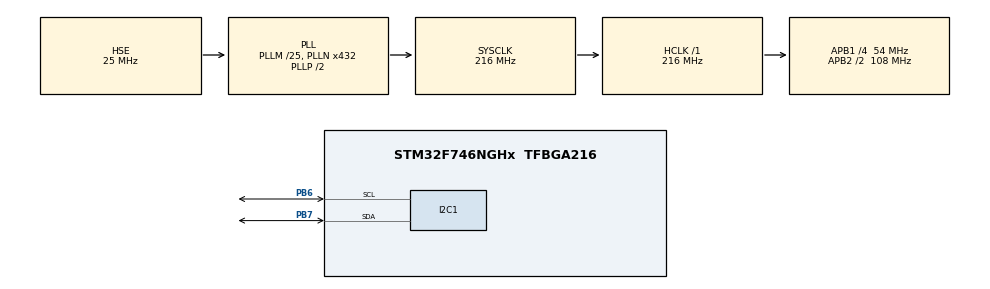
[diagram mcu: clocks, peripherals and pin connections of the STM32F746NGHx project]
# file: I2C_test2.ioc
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I2C1.Timing=0x20404768
Mcu.Family=STM32F7
Mcu.Name=STM32F746NGHx
Mcu.Package=TFBGA216
NVIC.PriorityGroup=NVIC_PRIORITYGROUP_4
PB6.GPIO_Pu=GPIO_PULLUP
PB6.Mode=I2C
PB6.Signal=I2C1_SCL
PB7.GPIO_Pu=GPIO_PULLUP
PB7.Mode=I2C
PB7.Signal=I2C1_SDA
PH0/OSC_IN.Mode=HSE-External-Oscillator
PH0/OSC_IN.Signal=RCC_OSC_IN
PH1/OSC_OUT.Mode=HSE-External-Oscillator
PH1/OSC_OUT.Signal=RCC_OSC_OUT
ProjectManager.HeapSize=0x200
ProjectManager.StackSize=0x400
ProjectManager.TargetToolchain=STM32CubeIDE
RCC.AHBFreq_Value=216000000
RCC.APB1CLKDivider=RCC_HCLK_DIV4
RCC.APB1Freq_Value=54000000
RCC.APB1TimFreq_Value=108000000
RCC.APB2CLKDivider=RCC_HCLK_DIV2
RCC.APB2Freq_Value=108000000
RCC.APB2TimFreq_Value=216000000
RCC.CortexFreq_Value=216000000
RCC.HCLKFreq_Value=216000000
RCC.HSE_VALUE=25000000
RCC.HSI_VALUE=16000000
RCC.PLL48CLockSelection=RCC_CLK48SOURCE_PLLSAIP
RCC.PLLI2SN=100
RCC.PLLM=25
RCC.PLLN=432
RCC.PLLQ=9
RCC.PLLSAIN=384
RCC.PLLSAIP=RCC_PLLSAIP_DIV8
RCC.PLLSAIR=5
RCC.PLLSAIRDiv=RCC_PLLSAIDIVR_8
RCC.PLLSourceVirtual=RCC_PLLSOURCE_HSE
RCC.SDMMCClockSelection=RCC_SDMMC1CLKSOURCE_CLK48
RCC.SYSCLKFreq_VALUE=216000000
RCC.SYSCLKSource=RCC_SYSCLKSOURCE_PLLCLK
RCC.USBFreq_Value=48000000
RCC.VCOOutputFreq_Value=432000000
board=STM32F746G-DISCO

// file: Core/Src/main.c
/* USER CODE BEGIN Header */
/**
  ******************************************************************************
  * @file           : main.c
  * @brief          : Main program body
  ******************************************************************************
  * @attention
  *
  * Copyright (c) 2025 STMicroelectronics.
  * All rights reserved.
  *
  * This software is licensed under terms that can be found in the LICENSE file
  * in the root directory of this software component.
  * If no LICENSE file comes with this software, it is provided AS-IS.
  *
  ******************************************************************************
  */
/* USER CODE END Header */
#include "main.h"
#include <string.h>
/* USER CODE BEGIN Includes */
/*7bit i2c address: 1010xxx
 * xxx depends on hardware: In our ram its EN | A9 | A8 | R/W
 * 7bits +1bit R/W
 * For factory RAM EN is 0, For application RAM EN is 1
 * After these 8 bits we need to add our address location (A7 - A0)
 * 0x50 is the device’s 7-bit address from the datasheet.
 * 0x50 << 1 (equals 0xA0) converts it to the 8-bit form STM32 HAL needs.*/
#define EEPROM_I2C_ADDR     (0xA2)    // 7-bit address shifted left for HAL
#define EEPROM_TIMEOUT      100				//This timeout defines how long the function will wait (block) for the I²C operation to complete before giving up and returning an error. It prevents your program from hanging forever if something goes wrong on the I²C bus (e.g., no device response, bus stuck, or hardware fault).
#define EEPROM_MEM_ADDR     0x00
uint8_t writeData[] = "Param";
uint8_t readData[sizeof(writeData)] = {0};
/* USER CODE END Includes */

I2C_HandleTypeDef hi2c1; //pointer to structure

void SystemClock_Config(void);
static void MX_GPIO_Init(void);
static void MX_I2C1_Init(void);

int main(void)
{

  /* USER CODE BEGIN 1 */
  HAL_Init();
  /* USER CODE END 1 */

  /* MCU Configuration--------------------------------------------------------*/

  /* Reset of all peripherals, Initializes the Flash interface and the Systick. */

  /* Configure the system clock */
  SystemClock_Config();

  /* Initialize all configured peripherals */
  MX_GPIO_Init();
  MX_I2C1_Init();
  /* USER CODE BEGIN 2 */
  /*
   * HAL_I2C_Master_Transmit(&hi2c1, EEPROM_I2C_ADDR | 0x00, data, size, timeout); // Write
  	 HAL_I2C_Master_Receive(&hi2c1,  EEPROM_I2C_ADDR | 0x01, data, size, timeout); // Read*/
  HAL_StatusTypeDef writeStatus = HAL_I2C_Mem_Write(
      &hi2c1,
      EEPROM_I2C_ADDR,
      EEPROM_MEM_ADDR,
      I2C_MEMADD_SIZE_8BIT,
      writeData,
      sizeof(writeData),
      EEPROM_TIMEOUT
  );

  HAL_Delay(5);  // EEPROM write cycle time

  /* EEPROM Read */
  HAL_StatusTypeDef readStatus = HAL_I2C_Mem_Read(
      &hi2c1,
      EEPROM_I2C_ADDR,
      EEPROM_MEM_ADDR,
      I2C_MEMADD_SIZE_8BIT,
      readData,
      sizeof(readData),
      EEPROM_TIMEOUT
  );

  /* Verify data */
  if (writeStatus == HAL_OK && readStatus == HAL_OK)
  {
      if (memcmp(writeData, readData, sizeof(writeData)) == 0)
      {
          // Data verified successfully
      }
      else
      {
          // Data mismatch
      }
  }
  /* USER CODE END 2 */

  /* Infinite loop */
  while (1)
  {

  }
}

void SystemClock_Config(void)
{
  RCC_OscInitTypeDef RCC_OscInitStruct = {0};
  RCC_ClkInitTypeDef RCC_ClkInitStruct = {0};

  /** Configure the main internal regulator output voltage
  */
  __HAL_RCC_PWR_CLK_ENABLE();
  __HAL_PWR_VOLTAGESCALING_CONFIG(PWR_REGULATOR_VOLTAGE_SCALE1);

  /** Initializes the RCC Oscillators according to the specified parameters
  * in the RCC_OscInitTypeDef structure.
  */
  RCC_OscInitStruct.OscillatorType = RCC_OSCILLATORTYPE_HSE;
  RCC_OscInitStruct.HSEState = RCC_HSE_ON;
  RCC_OscInitStruct.PLL.PLLState = RCC_PLL_ON;
  RCC_OscInitStruct.PLL.PLLSource = RCC_PLLSOURCE_HSE;
  RCC_OscInitStruct.PLL.PLLM = 25;
  RCC_OscInitStruct.PLL.PLLN = 432;
  RCC_OscInitStruct.PLL.PLLP = RCC_PLLP_DIV2;
  RCC_OscInitStruct.PLL.PLLQ = 9;
  if (HAL_RCC_OscConfig(&RCC_OscInitStruct) != HAL_OK)
  {
    Error_Handler();
  }

  /** Activate the Over-Drive mode
  */
  if (HAL_PWREx_EnableOverDrive() != HAL_OK)
  {
    Error_Handler();
  }

  /** Initializes the CPU, AHB and APB buses clocks
  */
  RCC_ClkInitStruct.ClockType = RCC_CLOCKTYPE_HCLK|RCC_CLOCKTYPE_SYSCLK
                              |RCC_CLOCKTYPE_PCLK1|RCC_CLOCKTYPE_PCLK2;
  RCC_ClkInitStruct.SYSCLKSource = RCC_SYSCLKSOURCE_PLLCLK;
  RCC_ClkInitStruct.AHBCLKDivider = RCC_SYSCLK_DIV1;
  RCC_ClkInitStruct.APB1CLKDivider = RCC_HCLK_DIV4;
  RCC_ClkInitStruct.APB2CLKDivider = RCC_HCLK_DIV2;

  if (HAL_RCC_ClockConfig(&RCC_ClkInitStruct, FLASH_LATENCY_7) != HAL_OK)
  {
    Error_Handler();
  }
}

static void MX_I2C1_Init(void)
{

  hi2c1.Instance = I2C1;
  hi2c1.Init.Timing = 0x20404768;
  hi2c1.Init.OwnAddress1 = 0;
  hi2c1.Init.AddressingMode = I2C_ADDRESSINGMODE_7BIT;
  hi2c1.Init.DualAddressMode = I2C_DUALADDRESS_DISABLE;
  hi2c1.Init.OwnAddress2 = 0;
  hi2c1.Init.OwnAddress2Masks = I2C_OA2_NOMASK;
  hi2c1.Init.GeneralCallMode = I2C_GENERALCALL_DISABLE;
  hi2c1.Init.NoStretchMode = I2C_NOSTRETCH_DISABLE;
  if (HAL_I2C_Init(&hi2c1) != HAL_OK)
  {
    Error_Handler();
  }

  /** Configure Analogue filter*/
/*It filters out very short noise pulses on the I²C lines (typically spikes shorter than ~50 ns).
It’s a hardware filter inside the MCU’s I²C peripheral that smooths out these glitches before the signal is processed by the I²C logic.
This helps avoid false start/stop conditions or bit errors caused by tiny electrical noise.

Digital Filter:
It filters noise after the analog stage, removing pulses shorter than a programmable number of peripheral clock cycles (can be 0 to 15 cycles).
It’s a configurable filter you can enable or disable depending on how noisy your environment is.*/
  if (HAL_I2CEx_ConfigAnalogFilter(&hi2c1, I2C_ANALOGFILTER_ENABLE) != HAL_OK)
  {
    Error_Handler();
  }

  /** Configure Digital filter
  */
  if (HAL_I2CEx_ConfigDigitalFilter(&hi2c1, 0) != HAL_OK)
  {
    Error_Handler();
  }

}

static void MX_GPIO_Init(void)
{

  /* GPIO Ports Clock Enable */
  __HAL_RCC_GPIOB_CLK_ENABLE();
  __HAL_RCC_GPIOH_CLK_ENABLE();

}

void Error_Handler(void)
{
  __disable_irq();
  while (1)
  {
  }
}
